VERSION "HIPBNYYYYYYYYYYYYYYYYYYYYYYYYYYYYYYYYYYYYY/4/%%%/4/'%**4YYY///"

NS_ :

BS_:

BU_:

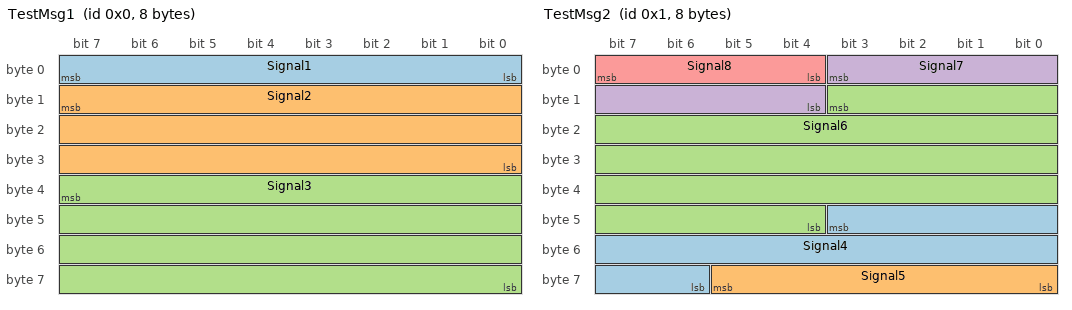
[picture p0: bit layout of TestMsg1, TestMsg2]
BO_ 0 TestMsg1: 8 Vector__XXX
 SG_ Signal1 : 7|8@0- (1,0) [0|0] "" Vector__XXX
 SG_ Signal2 : 15|24@0- (1,0) [0|0] "" Vector__XXX
 SG_ Signal3 : 39|32@0- (1,0) [0|0] "" Vector__XXX

BO_ 1 TestMsg2: 8 Vector__XXX
 SG_ Signal4 : 43|14@0+ (1,0) [0|0] "" Vector__XXX
 SG_ Signal5 : 61|6@0+ (1,0) [0|0] "" Vector__XXX
 SG_ Signal6 : 11|32@0- (1,0) [0|0] "" Vector__XXX
 SG_ Signal7 : 3|8@0- (1,0) [0|0] "" Vector__XXX
 SG_ Signal8 : 7|4@0+ (1,0) [0|0] "" Vector__XXX

BO_ 2 TestMsg3: 8 Vector__XXX
 SG_ Signal9 : 7|64@0- (1,0) [0|0] "" Vector__XXX

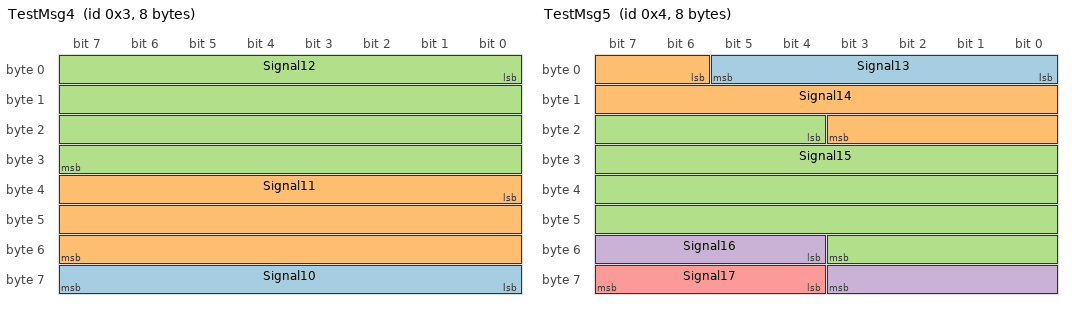
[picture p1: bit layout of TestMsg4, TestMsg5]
BO_ 3 TestMsg4: 8 Vector__XXX
 SG_ Signal10 : 56|8@1- (1,0) [0|0] "" Vector__XXX
 SG_ Signal11 : 32|24@1- (1,0) [0|0] "" Vector__XXX
 SG_ Signal12 : 0|32@1- (1,0) [0|0] "" Vector__XXX

BO_ 4 TestMsg5: 8 Vector__XXX
 SG_ Signal13 : 0|6@1+ (1,0) [0|0] "" Vector__XXX
 SG_ Signal14 : 6|14@1+ (1,0) [0|0] "" Vector__XXX
 SG_ Signal15 : 20|32@1- (1,0) [0|0] "" Vector__XXX
 SG_ Signal16 : 52|8@1- (1,0) [0|0] "" Vector__XXX
 SG_ Signal17 : 60|4@1+ (1,0) [0|0] "" Vector__XXX

SIG_VALTYPE_ 0 Signal3 : 1;
SIG_VALTYPE_ 1 Signal6 : 1;
SIG_VALTYPE_ 2 Signal9 : 2;
SIG_VALTYPE_ 3 Signal12 : 1;
SIG_VALTYPE_ 4 Signal15 : 1;
